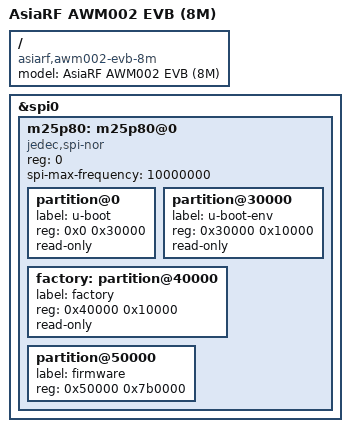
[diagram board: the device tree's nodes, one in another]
/dts-v1/;

#include "AWM002-EVB.dtsi"

/ {
	compatible = "asiarf,awm002-evb-8m", "ralink,rt5350-soc";
	model = "AsiaRF AWM002 EVB (8M)";
};

&spi0 {
	status = "okay";

	m25p80: m25p80@0 {
		#address-cells = <1>;
		#size-cells = <1>;
		reg = <0>;
		compatible = "jedec,spi-nor";
		spi-max-frequency = <10000000>;

		partition@0 {
			label = "u-boot";
			reg = <0x0 0x30000>;
			read-only;
		};

		partition@30000 {
			label = "u-boot-env";
			reg = <0x30000 0x10000>;
			read-only;
		};

		factory: partition@40000 {
			label = "factory";
			reg = <0x40000 0x10000>;
			read-only;
		};

		partition@50000 {
			label = "firmware";
			reg = <0x50000 0x7b0000>;
		};
	};
};
